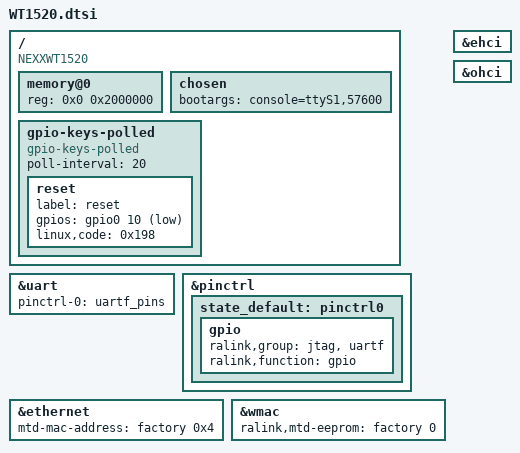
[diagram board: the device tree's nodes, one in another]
#include "rt5350.dtsi"

/ {
	compatible = "NEXXWT1520", "ralink,rt5350-soc";

	memory@0 {
		device_type = "memory";
		reg = <0x0 0x2000000>;
	};

	chosen {
		bootargs = "console=ttyS1,57600";
	};

	gpio-keys-polled {
		compatible = "gpio-keys-polled";
		#address-cells = <1>;
		#size-cells = <0>;
		poll-interval = <20>;
		reset {
			label = "reset";
			gpios = <&gpio0 10 1>;
			linux,code = <0x198>;
		};
	};
};

&uart {
	pinctrl-names = "default";
	pinctrl-0 = <&uartf_pins>;
	status = "okay";
};

&pinctrl {
	state_default: pinctrl0 {
		gpio {
			ralink,group = "jtag", "uartf";
			ralink,function = "gpio";
		};
	};
};

&ethernet {
	mtd-mac-address = <&factory 0x4>;
};

&wmac {
	ralink,mtd-eeprom = <&factory 0>;
};

&ehci {
	status = "okay";
};

&ohci {
	status = "okay";
};
